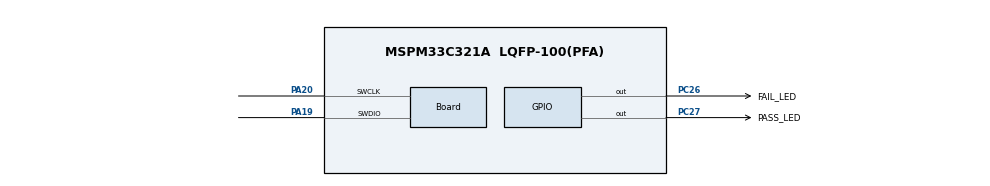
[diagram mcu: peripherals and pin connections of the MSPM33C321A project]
// @cliArgs --board /ti/boards/LP_MSPM33C321A --rtos nortos

//@cliArgs --device "MSPM33C321A" --package "LQFP-100(PFA)" --part "Default"
//@v2CliArgs --device "MSPM33C321A" --package "LQFP-100(PFA)"

/**
 * Import the modules used in this configuration.
 */
const AESADV = scripting.addModule("/ti/driverlib/AESADV");
const Board  = scripting.addModule("/ti/driverlib/Board");
const GPIO   = scripting.addModule("/ti/driverlib/GPIO", {}, false);
const GPIO1  = GPIO.addInstance();
const SYSCTL = scripting.addModule("/ti/driverlib/SYSCTL");

/**
 * Write custom configuration values to the imported modules.
 */
AESADV.keySize           = "DL_AESADV_KEY_SIZE_256_BIT";
AESADV.lowerCryptoLength = 0x10;
AESADV.enabledInterrupts = ["DL_AESADV_INTERRUPT_INPUT_READY","DL_AESADV_INTERRUPT_OUTPUT_READY"];

Board.peripheral.$assign          = "DEBUGSS";
Board.peripheral.swclkPin.$assign = "PA20";
Board.peripheral.swdioPin.$assign = "PA19";

GPIO1.$name                               = "GPIO_LEDS";
GPIO1.associatedPins.create(2);
GPIO1.associatedPins[0].$name             = "PASS_LED";
GPIO1.associatedPins[0].launchPadShortcut = "LED2GreenEn";
GPIO1.associatedPins[0].pin.$assign       = "PC27";
GPIO1.associatedPins[1].$name             = "FAIL_LED";
GPIO1.associatedPins[1].launchPadShortcut = "LED2RedEn";
GPIO1.associatedPins[1].pin.$assign       = "PC26";

SYSCTL.peripheral.$assign = "SYSCTL";

const ProjectConfig              = scripting.addModule("/ti/project_config/ProjectConfig", {}, false);
ProjectConfig.migrationCondition = true;
